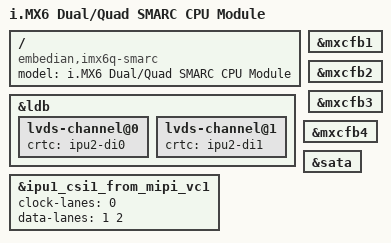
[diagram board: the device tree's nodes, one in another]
// SPDX-License-Identifier: GPL-2.0+
//
// Copyright 2012 Freescale Semiconductor, Inc.
// Copyright 2011 Linaro Ltd.
// Copyright 2023 Embedian.

/dts-v1/;

#include "imx6q.dtsi"
#include "imx6qdl-smarc.dtsi"

/ {
	model = "i.MX6 Dual/Quad SMARC CPU Module";
	compatible = "embedian,imx6q-smarc", "fsl,imx6q";
};

&ldb {
	lvds-channel@0 {
		crtc = "ipu2-di0";
	};

	lvds-channel@1 {
		crtc = "ipu2-di1";
	};
};

&mxcfb1 {
	status = "okay";
};

&mxcfb2 {
	status = "okay";
};

&mxcfb3 {
	status = "okay";
};

&mxcfb4 {
	status = "okay";
};

&sata {
	status = "okay";
};

&ipu1_csi1_from_mipi_vc1 {
	clock-lanes = <0>;
	data-lanes = <1 2>;
};
